VERSION ""

NS_ :

BS_:

BU_: XXX

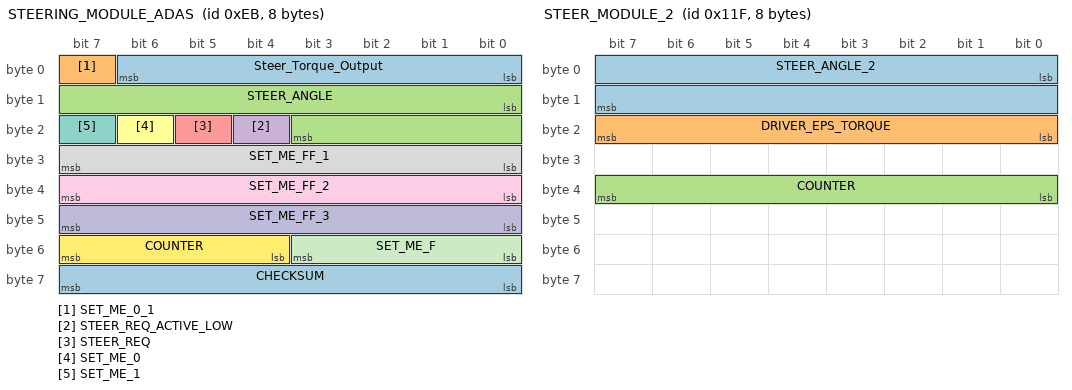
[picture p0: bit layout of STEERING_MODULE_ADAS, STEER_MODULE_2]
BO_ 235 STEERING_MODULE_ADAS: 8 XXX
 SG_ Steer_Torque_Output : 6|7@0+ (0.1,0) [0|127] "" XXX
 SG_ SET_ME_0_1 : 7|1@0+ (1,0) [0|0] "" XXX
 SG_ STEER_ANGLE : 8|12@1- (0.05,0) [-2048|2047] "" XXX
 SG_ STEER_REQ_ACTIVE_LOW : 20|1@0+ (1,0) [0|1] "" XXX
 SG_ STEER_REQ : 21|1@0+ (1,0) [0|1] "" XXX
 SG_ SET_ME_0 : 22|1@0+ (1,0) [0|0] "" XXX
 SG_ SET_ME_1 : 23|1@0+ (1,0) [1|1] "" XXX
 SG_ SET_ME_FF_1 : 31|8@0+ (1,0) [255|255] "" XXX
 SG_ SET_ME_FF_2 : 39|8@0+ (1,0) [255|255] "" XXX
 SG_ SET_ME_FF_3 : 47|8@0+ (1,0) [255|255] "" XXX
 SG_ SET_ME_F : 51|4@0+ (1,0) [15|15] "" XXX
 SG_ COUNTER : 52|4@1+ (1,0) [0|15] "" XXX
 SG_ CHECKSUM : 56|8@1+ (1,0) [0|255] "" XXX

BO_ 287 STEER_MODULE_2: 8 XXX
 SG_ STEER_ANGLE_2 : 0|16@1- (0.1,0) [0|65535] "" XXX
 SG_ DRIVER_EPS_TORQUE : 16|8@1+ (1,0) [0|255] "" XXX
 SG_ COUNTER : 39|8@0+ (1,0) [0|255] "" XXX

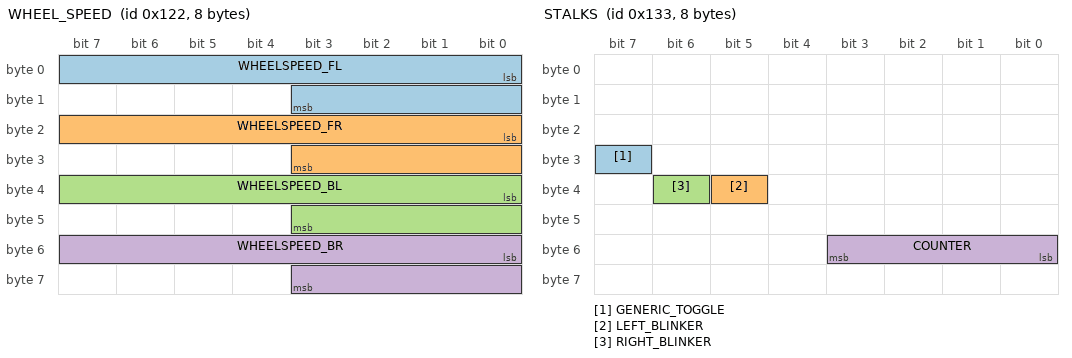
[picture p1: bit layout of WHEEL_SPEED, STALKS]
BO_ 290 WHEEL_SPEED: 8 XXX
 SG_ WHEELSPEED_FL : 0|12@1- (0.1,0) [0|255] "" XXX
 SG_ WHEELSPEED_FR : 16|12@1- (0.1,0) [0|255] "" XXX
 SG_ WHEELSPEED_BL : 32|12@1- (0.1,0) [0|255] "" XXX
 SG_ WHEELSPEED_BR : 48|12@1- (0.1,0) [0|255] "" XXX

BO_ 307 STALKS: 8 XXX
 SG_ GENERIC_TOGGLE : 31|1@0+ (1,0) [0|1] "" XXX
 SG_ LEFT_BLINKER : 37|1@0+ (1,0) [0|1] "" XXX
 SG_ RIGHT_BLINKER : 38|1@0+ (1,0) [0|1] "" XXX
 SG_ COUNTER : 48|4@1+ (1,0) [0|15] "" XXX

BO_ 455 STEERING_TORQUE: 64 XXX

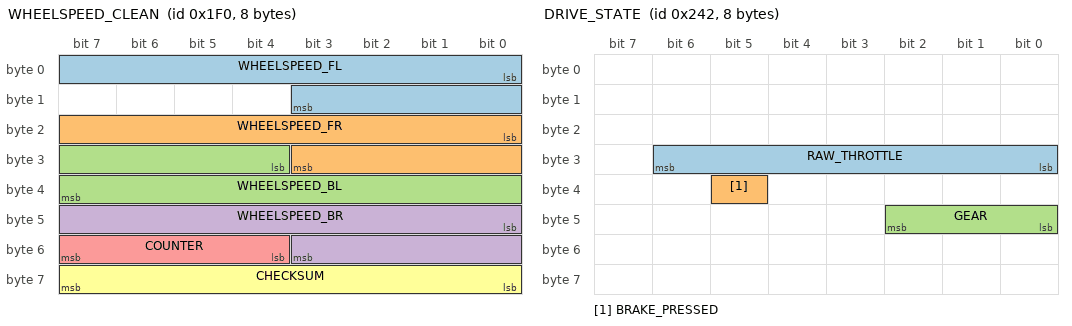
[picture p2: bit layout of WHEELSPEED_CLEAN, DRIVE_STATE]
BO_ 496 WHEELSPEED_CLEAN: 8 XXX
 SG_ WHEELSPEED_FL : 0|12@1- (0.05,0) [0|255] "" XXX
 SG_ WHEELSPEED_FR : 16|12@1- (0.05,0) [0|4095] "" XXX
 SG_ WHEELSPEED_BL : 28|12@1- (0.05,0) [0|4095] "" XXX
 SG_ WHEELSPEED_BR : 40|12@1- (0.05,0) [0|4095] "" XXX
 SG_ COUNTER : 55|4@0+ (1,0) [0|15] "" XXX
 SG_ CHECKSUM : 56|8@1+ (1,0) [0|255] "" XXX

BO_ 544 PEDAL_PRESSED: 8 XXX
 SG_ PEDAL_PRESSED_ACTIVE_LOW : 12|1@0+ (1,0) [0|1] "" XXX

BO_ 578 DRIVE_STATE: 8 XXX
 SG_ RAW_THROTTLE : 30|7@0+ (1,0) [0|127] "" XXX
 SG_ BRAKE_PRESSED : 37|1@0+ (1,0) [0|1] "" XXX
 SG_ GEAR : 40|3@1+ (1,0) [0|7] "" XXX

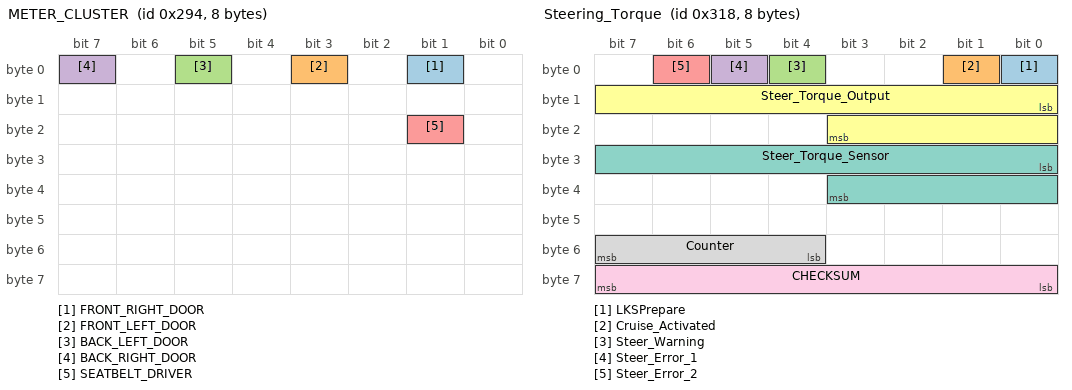
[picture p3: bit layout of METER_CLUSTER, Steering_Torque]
BO_ 660 METER_CLUSTER: 8 XXX
 SG_ FRONT_RIGHT_DOOR : 1|1@1+ (1,0) [0|511] "" XXX
 SG_ FRONT_LEFT_DOOR : 3|1@0+ (1,0) [0|1] "" XXX
 SG_ BACK_LEFT_DOOR : 5|1@1+ (1,0) [0|511] "" XXX
 SG_ BACK_RIGHT_DOOR : 7|1@0+ (1,0) [0|1] "" XXX
 SG_ SEATBELT_DRIVER : 17|1@0+ (1,0) [0|1] "" XXX

BO_ 692 ADAS2: 8 XXX

BO_ 790 LKAS_HUD_ADAS: 8 XXX
 SG_ HMA : 4|5@0+ (1,0) [0|7] "" XXX
 SG_ STEER_ACTIVE_1_1 : 5|1@0+ (1,0) [0|1] "" XXX
 SG_ LSS_STATE : 7|2@0+ (1,0) [0|1] "" XXX
 SG_ PT3 : 8|2@1+ (1,0) [0|3] "" XXX
 SG_ HAND_ON_WHEEL_WARNING : 10|1@0+ (1,0) [0|1] "" XXX
 SG_ PT2 : 11|5@1+ (1,0) [0|31] "" XXX
 SG_ SET_ME_XFF : 23|8@0+ (1,0) [0|255] "" XXX
 SG_ SET_ME_X5F : 31|8@0+ (1,0) [0|255] "" XXX
 SG_ SET_ME_1_2 : 32|1@0+ (1,0) [0|1] "" XXX
 SG_ PT5 : 33|2@1+ (1,0) [0|3] "" XXX
 SG_ STEER_ACTIVE_1_3 : 35|1@0+ (1,0) [0|1] "" XXX
 SG_ STEER_ACTIVE_ACTIVE_LOW : 36|1@0+ (1,0) [0|1] "" XXX
 SG_ STEER_ACTIVE_1_2 : 37|1@0+ (1,0) [0|1] "" XXX
 SG_ PT4 : 39|2@0+ (1,0) [0|3] "" XXX
 SG_ TSR : 47|8@0+ (1,0) [0|255] "" XXX
 SG_ SETTINGS : 48|4@1+ (1,0) [0|15] "" XXX
 SG_ COUNTER : 55|4@0+ (1,0) [0|15] "" XXX
 SG_ CHECKSUM : 63|8@0+ (1,0) [0|255] "" XXX

BO_ 792 Steering_Torque: 8 XXX
 SG_ LKSPrepare : 0|1@1+ (1,0) [0|1] "" XXX
 SG_ Cruise_Activated : 1|1@1+ (1,0) [0|1] "" XXX
 SG_ Steer_Warning : 4|1@1+ (1,0) [0|1] "" XXX
 SG_ Steer_Error_1 : 5|1@1+ (1,0) [0|1] "" XXX
 SG_ Steer_Error_2 : 6|1@1+ (1,0) [0|1] "" XXX
 SG_ Steer_Torque_Output : 8|12@1- (1,0) [-2048|2047] "" XXX
 SG_ Steer_Torque_Sensor : 24|12@1- (1,0) [-2048|2047] "" XXX
 SG_ Counter : 52|4@1+ (1,0) [0|15] "" XXX
 SG_ CHECKSUM : 56|8@1+ (1,0) [0|255] "" XXX

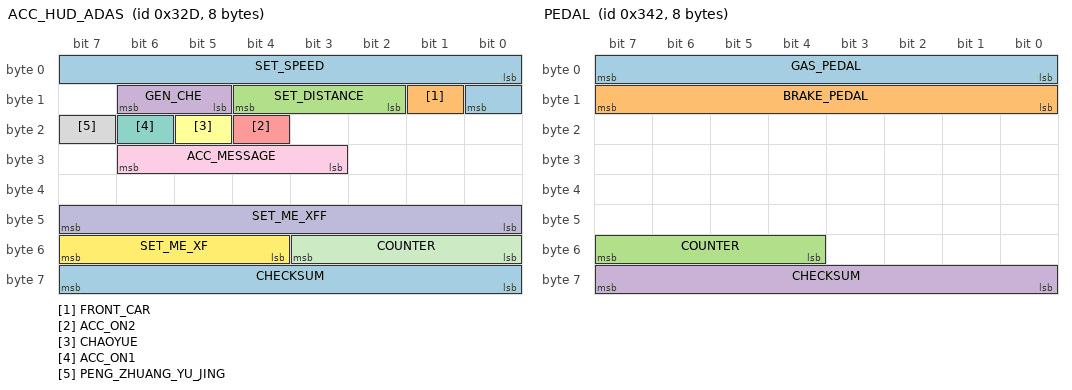
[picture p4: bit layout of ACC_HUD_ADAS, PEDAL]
BO_ 813 ACC_HUD_ADAS: 8 XXX
 SG_ SET_SPEED : 0|9@1+ (5,0) [0|255] "" XXX
 SG_ FRONT_CAR : 9|1@0+ (1,0) [0|1] "" XXX
 SG_ SET_DISTANCE : 12|3@0+ (1,0) [0|7] "" XXX
 SG_ GEN_CHE : 14|2@0+ (1,0) [0|3] "" XXX
 SG_ ACC_ON2 : 20|1@0+ (1,0) [0|1] "" XXX
 SG_ CHAOYUE : 21|1@0+ (1,0) [0|1] "" XXX
 SG_ ACC_ON1 : 22|1@0+ (1,0) [0|1] "" XXX
 SG_ PENG_ZHUANG_YU_JING : 23|1@0+ (1,0) [0|1] "" XXX
 SG_ ACC_MESSAGE : 30|4@0+ (1,0) [0|15] "" XXX
 SG_ SET_ME_XFF : 47|8@0+ (1,0) [0|255] "" XXX
 SG_ COUNTER : 48|4@1+ (1,0) [0|15] "" XXX
 SG_ SET_ME_XF : 55|4@0+ (1,0) [0|15] "" XXX
 SG_ CHECKSUM : 56|8@1+ (1,0) [0|255] "" XXX

BO_ 814 ACC_CMD: 8 XXX
 SG_ ACCEL_CMD : 0|8@1+ (1,-100) [0|255] "" XXX
 SG_ ACC_ON_1 : 9|1@0+ (1,0) [0|1] "" XXX
 SG_ SET_ME_25_1 : 10|6@1+ (1,0) [0|255] "" XXX
 SG_ ACC_ON_2 : 17|1@0+ (1,0) [0|1] "" XXX
 SG_ SET_ME_24_2 : 18|6@1+ (1,0) [0|255] "" XXX
 SG_ DECEL_FACTOR : 24|4@1+ (1,0) [0|15] "" XXX
 SG_ SET_ME_X8 : 31|4@0+ (1,0) [0|255] "" XXX
 SG_ ACCEL_FACTOR : 32|4@1+ (1,0) [0|15] "" XXX
 SG_ CMD_REQ_ACTIVE_LOW : 36|1@0+ (1,0) [0|255] "" XXX
 SG_ SET_ME_1 : 38|1@0+ (1,0) [0|1] "" XXX
 SG_ STANDSTILL_RESUME : 39|1@0+ (1,0) [0|1] "" XXX
 SG_ STANDSTILL_STATE : 40|1@0+ (1,0) [0|1] "" XXX
 SG_ ACC_REQ_NOT_STANDSTILL : 43|1@0+ (1,0) [0|1] "" XXX
 SG_ ACC_CONTROLLABLE_AND_ON : 44|1@0+ (1,0) [0|1] "" XXX
 SG_ ACC_OVERRIDE_OR_STANDSTILL : 45|1@0+ (1,0) [0|1] "" XXX
 SG_ COUNTER : 48|4@1+ (1,0) [0|15] "" XXX
 SG_ SET_ME_XF : 55|4@0+ (1,0) [0|15] "" XXX
 SG_ CHECKSUM : 56|8@1+ (1,0) [0|255] "" XXX

BO_ 815 ADAS3: 8 XXX

BO_ 834 PEDAL: 8 XXX
 SG_ GAS_PEDAL : 0|8@1+ (0.01,0) [0|255] "" XXX
 SG_ BRAKE_PEDAL : 8|8@1+ (0.01,0) [0|255] "" XXX
 SG_ COUNTER : 55|4@0+ (1,0) [0|15] "" XXX
 SG_ CHECKSUM : 56|8@1+ (1,0) [0|255] "" XXX

BO_ 843 ADAS4: 8 XXX

BO_ 884 ADAS5: 8 XXX

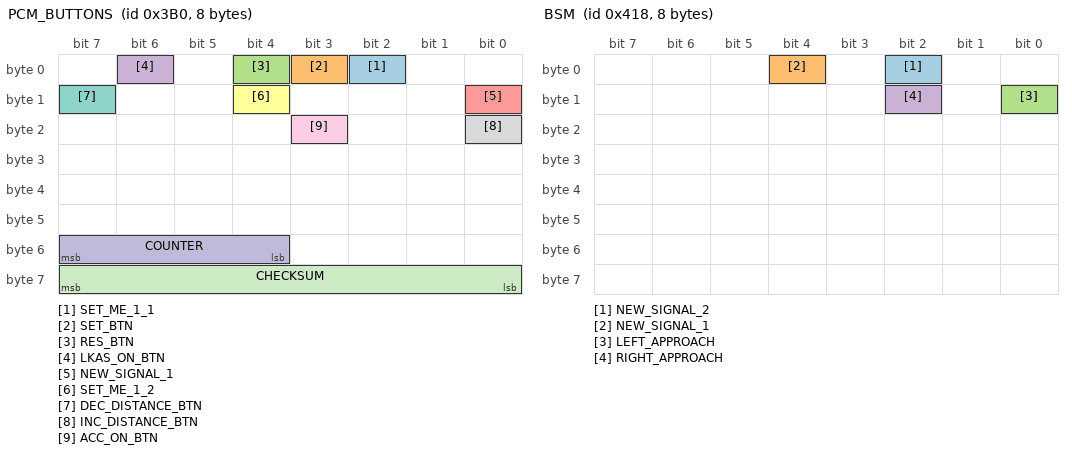
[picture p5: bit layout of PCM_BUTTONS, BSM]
BO_ 944 PCM_BUTTONS: 8 XXX
 SG_ SET_ME_1_1 : 2|1@0+ (1,0) [0|1] "" XXX
 SG_ SET_BTN : 3|1@0+ (1,0) [0|1] "" XXX
 SG_ RES_BTN : 4|1@0+ (1,0) [0|1] "" XXX
 SG_ LKAS_ON_BTN : 6|1@0+ (1,0) [0|1] "" XXX
 SG_ NEW_SIGNAL_1 : 8|1@0+ (1,0) [0|1] "" XXX
 SG_ SET_ME_1_2 : 12|1@0+ (1,0) [0|1] "" XXX
 SG_ DEC_DISTANCE_BTN : 15|1@0+ (1,0) [0|1] "" XXX
 SG_ INC_DISTANCE_BTN : 16|1@0+ (1,0) [0|1] "" XXX
 SG_ ACC_ON_BTN : 19|1@0+ (1,0) [0|1] "" XXX
 SG_ COUNTER : 55|4@0+ (1,0) [0|15] "" XXX
 SG_ CHECKSUM : 63|8@0+ (1,0) [0|255] "" XXX

BO_ 1036 NEW_MSG_40C: 8 XXX
 SG_ NEW_SIGNAL_1 : 9|2@0+ (1,0) [0|3] "" XXX

BO_ 1048 BSM: 8 XXX
 SG_ NEW_SIGNAL_2 : 2|1@0+ (1,0) [0|1] "" XXX
 SG_ NEW_SIGNAL_1 : 4|1@0+ (1,0) [0|1] "" XXX
 SG_ LEFT_APPROACH : 8|1@0+ (1,0) [0|1] "" XXX
 SG_ RIGHT_APPROACH : 10|1@0+ (1,0) [0|1] "" XXX

BO_ 1192 An_Jian: 8 XXX
 SG_ NEW_SIGNAL_1 : 13|6@0+ (1,0) [0|63] "" XXX

VAL_ 578 GEAR 4 "D" 2 "R" 1 "P";
VAL_ 813 SET_DISTANCE 4 "4bar" 3 "3bar" 2 "2bar" 1 "1bar";
VAL_ 1192 NEW_SIGNAL_1 1 "VOL_UP" 4 "VOL_DOWN" 35 "MENU" 21 "360" 37 "Xuanzhuan" 12 "Phone" 19 "XIAODI" 20 "NULL";
